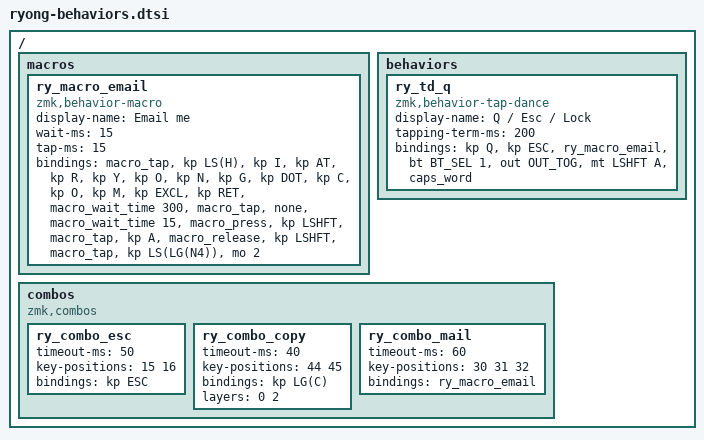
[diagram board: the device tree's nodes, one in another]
/*
 * Generated by key.ryong.com — edit in the Behaviors editor, not by hand.
 * Source of truth: ryong-behaviors.json in this folder.
 */

#include <dt-bindings/zmk/keys.h>
#include <dt-bindings/zmk/bt.h>
#include <dt-bindings/zmk/outputs.h>

/ {
    macros {
        ry_macro_email: ry_macro_email {
            compatible = "zmk,behavior-macro";
            #binding-cells = <0>;
            display-name = "Email me";
            wait-ms = <15>;
            tap-ms = <15>;
            bindings
                = <&macro_tap &kp LS(H) &kp I &kp AT &kp R &kp Y &kp O &kp N &kp G &kp DOT &kp C &kp O &kp M &kp EXCL &kp RET>
                , <&macro_wait_time 300>
                , <&macro_tap &none>
                , <&macro_wait_time 15>
                , <&macro_press &kp LSHFT>
                , <&macro_tap &kp A>
                , <&macro_release &kp LSHFT>
                , <&macro_tap &kp LS(LG(N4)) &mo 2>
                ;
        };
    };

    behaviors {
        ry_td_q: ry_td_q {
            compatible = "zmk,behavior-tap-dance";
            #binding-cells = <0>;
            display-name = "Q / Esc / Lock";
            tapping-term-ms = <200>;
            bindings = <&kp Q>, <&kp ESC>, <&ry_macro_email>, <&bt BT_SEL 1>, <&out OUT_TOG>, <&mt LSHFT A>, <&caps_word>;
        };
    };

    combos {
        compatible = "zmk,combos";
        ry_combo_esc {
            timeout-ms = <50>;
            key-positions = <15 16>;
            bindings = <&kp ESC>;
        };
        ry_combo_copy {
            timeout-ms = <40>;
            key-positions = <44 45>;
            bindings = <&kp LG(C)>;
            layers = <0 2>;
        };
        ry_combo_mail {
            timeout-ms = <60>;
            key-positions = <30 31 32>;
            bindings = <&ry_macro_email>;
        };
    };
};
